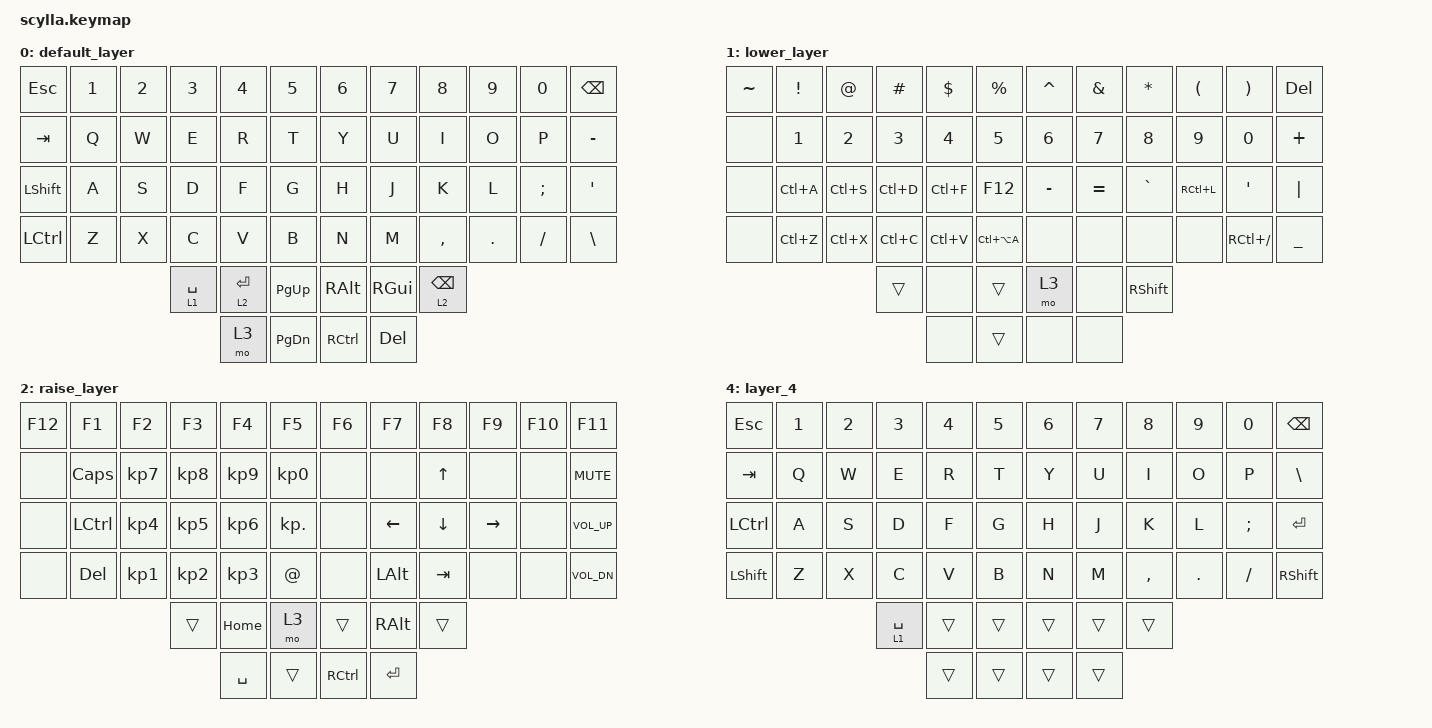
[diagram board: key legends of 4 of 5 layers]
#include <behaviors.dtsi>
#include <dt-bindings/zmk/bt.h>
#include <dt-bindings/zmk/keys.h>

#define DEFAULT 0
#define LWR 1
#define RSE 2
#define ADJ 3

/ {
    combos {
        compatible = "zmk,combos";

        combo1 {
            bindings = <&kp K_MUTE>;
            key-positions = <50 55>;
            layers = <1>;
        };

        combo2 {
            bindings = <&kp RBKT>;
            key-positions = <19 20>;
        };

        combo3 {
            bindings = <&kp LEFT_PARENTHESIS>;
            key-positions = <27 28>;
        };

        combo4 {
            bindings = <&kp RIGHT_PARENTHESIS>;
            key-positions = <31 32>;
        };

        combo5 {
            bindings = <&kp LEFT_BRACE>;
            key-positions = <39 40>;
        };

        combo6 {
            bindings = <&kp RIGHT_BRACE>;
            key-positions = <43 44>;
        };

        combo7 {
            bindings = <&kp BACKSLASH>;
            key-positions = <17 18>;
        };

        combo8 {
            bindings = <&kp PIPE>;
            key-positions = <29 30>;
        };

        combo9 {
            bindings = <&kp ESC>;
            key-positions = <13 14>;
        };

        combo10 {
            bindings = <&kp TAB>;
            key-positions = <25 26>;
        };
    };

    behaviors {
        ltq: ltq {
            compatible = "zmk,behavior-hold-tap";
            label = "LTQ";
            bindings = <&mo>, <&kp>;

            #binding-cells = <2>;
            tapping-term-ms = <200>;
            quick-tap-ms = <180>;
            global-quick-tap;
        };
    };

    macros {
        jingyin: jingyin {
            compatible = "zmk,behavior-macro";
            #binding-cells = <0>;
            bindings = <&kp LEFT_ALT &kp LSHIFT>;
            label = "JINGYIN";
        };
        new_macro: new_macro {
            compatible = "zmk,behavior-macro";
            #binding-cells = <0>;
            bindings = <&none>;
            label = "NEW_MACRO";
        };
    };

    keymap {
        compatible = "zmk,keymap";

        default_layer {
            bindings = <
&kp ESC     &kp N1  &kp N2  &kp N3       &kp N4       &kp N5           &kp N6         &kp N7         &kp N8            &kp N9   &kp N0    &kp BSPC
&kp TAB     &kp Q   &kp W   &kp E        &kp R        &kp T            &kp Y          &kp U          &kp I             &kp O    &kp P     &kp MINUS
&kp LSHIFT  &kp A   &kp S   &kp D        &kp F        &kp G            &kp H          &kp J          &kp K             &kp L    &kp SEMI  &kp SQT
&kp LCTRL   &kp Z   &kp X   &kp C        &kp V        &kp B            &kp N          &kp M          &kp COMMA         &kp DOT  &kp FSLH  &kp BSLH
                            &lt 1 SPACE  &lt 2 ENTER  &kp PAGE_UP      &kp RIGHT_ALT  &kp RIGHT_GUI  &ltq 2 BACKSPACE
                                         &mo 3        &kp PAGE_DOWN    &kp RCTRL      &kp DEL
            >;
        };

        lower_layer {
            bindings = <
&kp TILDE  &kp EXCL      &kp AT        &kp HASH      &kp DLLR      &kp PRCNT        &kp CARET     &kp AMPS      &kp ASTRK        &kp LPAR      &kp RPAR       &kp DEL
&none      &kp NUMBER_1  &kp NUMBER_2  &kp NUMBER_3  &kp NUMBER_4  &kp NUMBER_5     &kp NUMBER_6  &kp NUMBER_7  &kp NUMBER_8     &kp NUMBER_9  &kp NUMBER_0   &kp PLUS
&none      &kp LC(A)     &kp LC(S)     &kp LC(D)     &kp LC(F)     &kp F12          &kp MINUS     &kp EQUAL     &kp GRAVE        &kp RC(L)     &kp SQT        &kp PIPE
&none      &kp LC(Z)     &kp LC(X)     &kp LC(C)     &kp LC(V)     &kp LC(LA(A))    &none         &none         &none            &none         &kp RC(SLASH)  &kp UNDER
                                       &trans        &none         &trans           &mo 3         &none         &kp RIGHT_SHIFT
                                                     &none         &trans           &none         &none
            >;
        };

        raise_layer {
            bindings = <
&kp F12  &kp F1     &kp F2           &kp F3           &kp F4           &kp F5             &kp F6     &kp F7        &kp F8    &kp F9     &kp F10  &kp F11
&none    &kp CAPS   &kp KP_NUMBER_7  &kp KP_NUMBER_8  &kp KP_NUMBER_9  &kp KP_NUMBER_0    &none      &none         &kp UP    &none      &none    &kp C_MUTE
&none    &kp LCTRL  &kp KP_NUMBER_4  &kp KP_NUMBER_5  &kp KP_NUMBER_6  &kp KP_DOT         &none      &kp LEFT      &kp DOWN  &kp RIGHT  &none    &kp C_VOL_UP
&none    &kp DEL    &kp KP_NUMBER_1  &kp KP_NUMBER_2  &kp KP_NUMBER_3  &kp AT_SIGN        &none      &kp LEFT_ALT  &kp TAB   &none      &none    &kp C_VOL_DN
                                     &trans           &kp HOME         &mo 3              &trans     &kp RALT      &trans
                                                      &kp SPACE        &trans             &kp RCTRL  &kp RET
            >;
        };

        adjust_layer {
            bindings = <
&bt BT_CLR  &bt BT_SEL 0  &bt BT_SEL 1  &bt BT_SEL 2  &bt BT_SEL 3  &bt BT_SEL 4    &none  &none  &none  &none  &none  &none
&none       &none         &none         &none         &none         &none           &none  &none  &none  &none  &none  &none
&none       &none         &none         &none         &none         &none           &none  &none  &none  &none  &none  &bt BT_CLR
&none       &none         &none         &none         &bootloader   &none           &none  &none  &none  &none  &none  &none
                                        &none         &none         &none           &none  &none  &none
                                                      &none         &none           &none
            >;
        };

        layer_4 {
            bindings = <
&kp ESC    &kp N1  &kp N2  &kp N3       &kp N4  &kp N5    &kp N6  &kp N7  &kp N8     &kp N9   &kp N0    &kp BACKSPACE
&kp TAB    &kp Q   &kp W   &kp E        &kp R   &kp T     &kp Y   &kp U   &kp I      &kp O    &kp P     &kp BSLH
&kp LCTRL  &kp A   &kp S   &kp D        &kp F   &kp G     &kp H   &kp J   &kp K      &kp L    &kp SEMI  &kp ENTER
&kp LSHFT  &kp Z   &kp X   &kp C        &kp V   &kp B     &kp N   &kp M   &kp COMMA  &kp DOT  &kp FSLH  &kp RSHIFT
                           &lt 1 SPACE  &trans  &trans    &trans  &trans  &trans
                                        &trans  &trans    &trans  &trans
            >;
        };
    };
};
